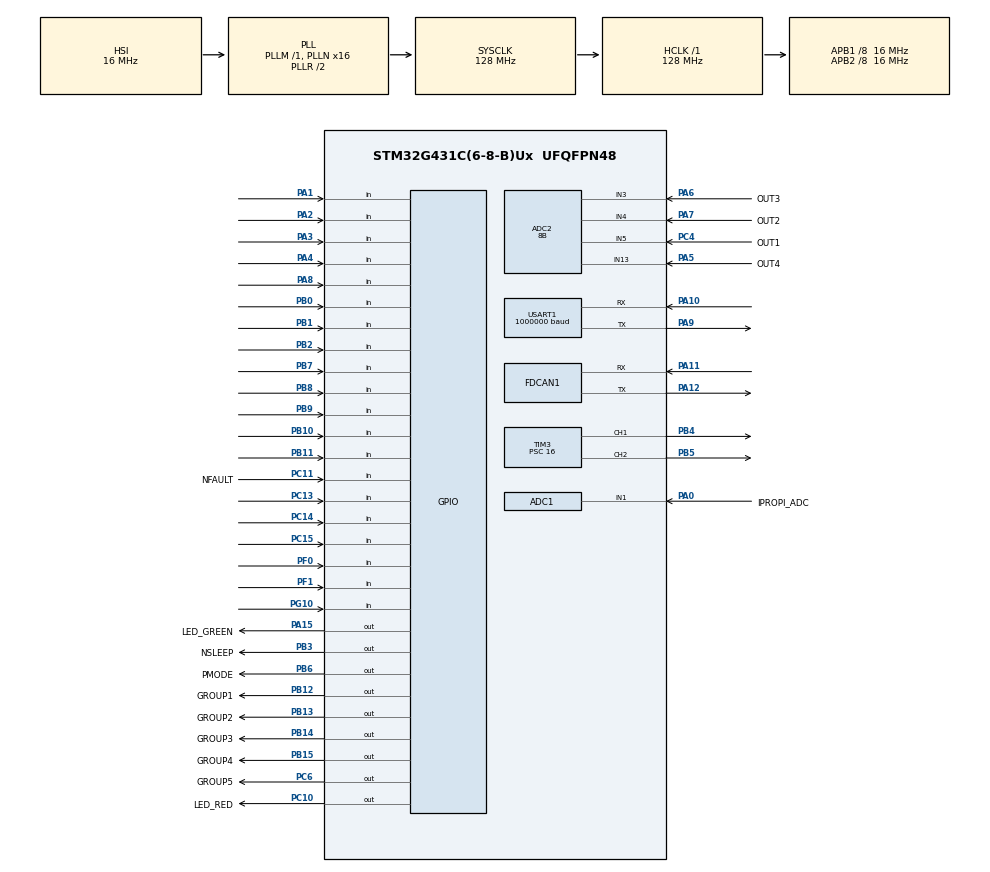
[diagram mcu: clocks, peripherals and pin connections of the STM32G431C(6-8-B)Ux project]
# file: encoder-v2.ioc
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ADC1.Channel-0\#ChannelRegularConversion=ADC_CHANNEL_1
ADC1.NbrOfConversionFlag=1
ADC1.OffsetNumber-0\#ChannelRegularConversion=ADC_OFFSET_NONE
ADC1.Rank-0\#ChannelRegularConversion=1
ADC1.SamplingTime-0\#ChannelRegularConversion=ADC_SAMPLETIME_2CYCLES_5
ADC1.master=1
ADC2.Channel-0\#ChannelRegularConversion=ADC_CHANNEL_5
ADC2.Channel-1\#ChannelRegularConversion=ADC_CHANNEL_4
ADC2.Channel-2\#ChannelRegularConversion=ADC_CHANNEL_3
ADC2.Channel-3\#ChannelRegularConversion=ADC_CHANNEL_13
ADC2.DMAContinuousRequests=ENABLE
ADC2.EOCSelection=ADC_EOC_SEQ_CONV
ADC2.NbrOfConversion=4
ADC2.NbrOfConversionFlag=1
ADC2.OffsetNumber-0\#ChannelRegularConversion=ADC_OFFSET_NONE
ADC2.OffsetNumber-1\#ChannelRegularConversion=ADC_OFFSET_NONE
ADC2.OffsetNumber-2\#ChannelRegularConversion=ADC_OFFSET_NONE
ADC2.OffsetNumber-3\#ChannelRegularConversion=ADC_OFFSET_NONE
ADC2.Rank-0\#ChannelRegularConversion=1
ADC2.Rank-1\#ChannelRegularConversion=2
ADC2.Rank-2\#ChannelRegularConversion=3
ADC2.Rank-3\#ChannelRegularConversion=4
ADC2.Resolution=ADC_RESOLUTION_8B
ADC2.SamplingTime-0\#ChannelRegularConversion=ADC_SAMPLETIME_47CYCLES_5
ADC2.SamplingTime-1\#ChannelRegularConversion=ADC_SAMPLETIME_47CYCLES_5
ADC2.SamplingTime-2\#ChannelRegularConversion=ADC_SAMPLETIME_47CYCLES_5
ADC2.SamplingTime-3\#ChannelRegularConversion=ADC_SAMPLETIME_47CYCLES_5
Dma.ADC2.0.Direction=DMA_PERIPH_TO_MEMORY
Dma.ADC2.0.EventEnable=DISABLE
Dma.ADC2.0.Instance=DMA1_Channel1
Dma.ADC2.0.MemDataAlignment=DMA_MDATAALIGN_BYTE
Dma.ADC2.0.MemInc=DMA_MINC_ENABLE
Dma.ADC2.0.Mode=DMA_NORMAL
Dma.ADC2.0.PeriphDataAlignment=DMA_PDATAALIGN_HALFWORD
Dma.ADC2.0.PeriphInc=DMA_PINC_DISABLE
Dma.ADC2.0.Polarity=HAL_DMAMUX_REQ_GEN_RISING
Dma.ADC2.0.Priority=DMA_PRIORITY_LOW
Dma.ADC2.0.RequestNumber=1
Dma.ADC2.0.SignalID=NONE
Dma.ADC2.0.SyncEnable=DISABLE
Dma.ADC2.0.SyncPolarity=HAL_DMAMUX_SYNC_NO_EVENT
Dma.ADC2.0.SyncRequestNumber=1
Dma.ADC2.0.SyncSignalID=NONE
Dma.Request0=ADC2
FDCAN1.AutoRetransmission=ENABLE
FDCAN1.ClockDivider=FDCAN_CLOCK_DIV1
FDCAN1.DataSyncJumpWidth=4
FDCAN1.DataTimeSeg1=11
FDCAN1.DataTimeSeg2=4
FDCAN1.NominalSyncJumpWidth=4
FDCAN1.NominalTimeSeg1=11
FDCAN1.NominalTimeSeg2=4
Mcu.Family=STM32G4
Mcu.Name=STM32G431C(6-8-B)Ux
Mcu.Package=UFQFPN48
NVIC.DMA1_Channel1_IRQn=true\:0\:0\:false\:false\:true\:false\:true
NVIC.FDCAN1_IT0_IRQn=true\:0\:0\:false\:false\:true\:true\:true
NVIC.PriorityGroup=NVIC_PRIORITYGROUP_4
PA0.GPIO_Label=IPROPI_ADC
PA0.Mode=IN1-Single-Ended
PA0.Signal=ADC1_IN1
PA1.GPIO_Mode=GPIO_MODE_INPUT
PA1.GPIO_PuPd=GPIO_PULLDOWN
PA1.Signal=GPIO_Input
PA10.Mode=Asynchronous
PA10.Signal=USART1_RX
PA11.Mode=FDCAN_Activate
PA11.Signal=FDCAN1_RX
PA12.Mode=FDCAN_Activate
PA12.Signal=FDCAN1_TX
PA13.Mode=Serial_Wire
PA13.Signal=SYS_JTMS-SWDIO
PA14.Mode=Serial_Wire
PA14.Signal=SYS_JTCK-SWCLK
PA15.GPIO_Label=LED_GREEN
PA15.Signal=GPIO_Output
PA2.GPIO_Mode=GPIO_MODE_INPUT
PA2.GPIO_PuPd=GPIO_PULLDOWN
PA2.Signal=GPIO_Input
PA3.GPIO_Mode=GPIO_MODE_INPUT
PA3.GPIO_PuPd=GPIO_PULLDOWN
PA3.Signal=GPIO_Input
PA4.GPIO_Mode=GPIO_MODE_INPUT
PA4.GPIO_PuPd=GPIO_PULLDOWN
PA4.Signal=GPIO_Input
PA5.GPIO_Label=OUT4
PA5.Mode=IN13-Single-Ended
PA5.Signal=ADC2_IN13
PA6.GPIO_Label=OUT3
PA6.Mode=IN3-Single-Ended
PA6.Signal=ADC2_IN3
PA7.GPIO_Label=OUT2
PA7.Mode=IN4-Single-Ended
PA7.Signal=ADC2_IN4
PA8.GPIO_Mode=GPIO_MODE_INPUT
PA8.GPIO_PuPd=GPIO_PULLDOWN
PA8.Signal=GPIO_Input
PA9.Mode=Asynchronous
PA9.Signal=USART1_TX
PB0.GPIO_Mode=GPIO_MODE_INPUT
PB0.GPIO_PuPd=GPIO_PULLDOWN
PB0.Signal=GPIO_Input
PB1.GPIO_Mode=GPIO_MODE_INPUT
PB1.GPIO_PuPd=GPIO_PULLDOWN
PB1.Signal=GPIO_Input
PB10.GPIO_Mode=GPIO_MODE_INPUT
PB10.GPIO_PuPd=GPIO_PULLDOWN
PB10.Signal=GPIO_Input
PB11.GPIO_Mode=GPIO_MODE_INPUT
PB11.GPIO_PuPd=GPIO_PULLDOWN
PB11.Signal=GPIO_Input
PB12.GPIO_Label=GROUP1
PB12.GPIO_Speed=GPIO_SPEED_FREQ_HIGH
PB12.PinState=GPIO_PIN_RESET
PB12.Signal=GPIO_Output
PB13.GPIO_Label=GROUP2
PB13.GPIO_Speed=GPIO_SPEED_FREQ_HIGH
PB13.PinState=GPIO_PIN_RESET
PB13.Signal=GPIO_Output
PB14.GPIO_Label=GROUP3
PB14.GPIO_Speed=GPIO_SPEED_FREQ_HIGH
PB14.Signal=GPIO_Output
PB15.GPIO_Label=GROUP4
PB15.GPIO_Speed=GPIO_SPEED_FREQ_HIGH
PB15.Signal=GPIO_Output
PB2.GPIO_Mode=GPIO_MODE_INPUT
PB2.GPIO_PuPd=GPIO_PULLDOWN
PB2.Signal=GPIO_Input
PB3.GPIO_Label=NSLEEP
PB3.Signal=GPIO_Output
PB4.Signal=S_TIM3_CH1
PB5.Signal=S_TIM3_CH2
PB6.GPIO_Label=PMODE
PB6.PinState=GPIO_PIN_SET
PB6.Signal=GPIO_Output
PB7.GPIO_Mode=GPIO_MODE_INPUT
PB7.GPIO_PuPd=GPIO_PULLDOWN
PB7.Signal=GPIO_Input
PB8-BOOT0.GPIO_Mode=GPIO_MODE_INPUT
PB8-BOOT0.GPIO_PuPd=GPIO_PULLDOWN
PB8-BOOT0.Signal=GPIO_Input
PB9.GPIO_Mode=GPIO_MODE_INPUT
PB9.GPIO_PuPd=GPIO_PULLDOWN
PB9.Signal=GPIO_Input
PC10.GPIO_Label=LED_RED
PC10.Signal=GPIO_Output
PC11.GPIO_Label=NFAULT
PC11.Signal=GPIO_Input
PC13.GPIO_Mode=GPIO_MODE_INPUT
PC13.GPIO_PuPd=GPIO_PULLDOWN
PC13.Signal=GPIO_Input
PC14-OSC32_IN.GPIO_Mode=GPIO_MODE_INPUT
PC14-OSC32_IN.GPIO_PuPd=GPIO_PULLDOWN
PC14-OSC32_IN.Signal=GPIO_Input
PC15-OSC32_OUT.GPIO_Mode=GPIO_MODE_INPUT
PC15-OSC32_OUT.GPIO_PuPd=GPIO_PULLDOWN
PC15-OSC32_OUT.Signal=GPIO_Input
PC4.GPIO_Label=OUT1
PC4.Mode=IN5-Single-Ended
PC4.Signal=ADC2_IN5
PC6.GPIO_Label=GROUP5
PC6.GPIO_Speed=GPIO_SPEED_FREQ_HIGH
PC6.Signal=GPIO_Output
PF0-OSC_IN.GPIO_Mode=GPIO_MODE_INPUT
PF0-OSC_IN.GPIO_PuPd=GPIO_PULLDOWN
PF0-OSC_IN.Signal=GPIO_Input
PF1-OSC_OUT.GPIO_Mode=GPIO_MODE_INPUT
PF1-OSC_OUT.GPIO_PuPd=GPIO_PULLDOWN
PF1-OSC_OUT.Signal=GPIO_Input
PG10-NRST.GPIO_PuPd=GPIO_PULLUP
PG10-NRST.Signal=GPIO_Input
ProjectManager.HeapSize=0x200
ProjectManager.StackSize=0x400
ProjectManager.TargetToolchain=STM32CubeIDE
RCC.ADC12Freq_Value=128000000
RCC.AHBFreq_Value=128000000
RCC.APB1CLKDivider=RCC_HCLK_DIV8
RCC.APB1Freq_Value=16000000
RCC.APB1TimFreq_Value=32000000
RCC.APB2CLKDivider=RCC_HCLK_DIV8
RCC.APB2Freq_Value=16000000
RCC.APB2TimFreq_Value=32000000
RCC.CortexFreq_Value=16000000
RCC.Cortex_Div=SYSTICK_CLKSOURCE_HCLK_DIV8
RCC.EXTERNAL_CLOCK_VALUE=12288000
RCC.HCLKFreq_Value=128000000
RCC.HSE_VALUE=8000000
RCC.HSI48_VALUE=48000000
RCC.HSI_VALUE=16000000
RCC.LSE_VALUE=32768
RCC.PLLN=16
RCC.SYSCLKFreq_VALUE=128000000
RCC.SYSCLKSource=RCC_SYSCLKSOURCE_PLLCLK
RCC.USBFreq_Value=128000000
RCC.VCOOutputFreq_Value=256000000
SH.S_TIM3_CH1.0=TIM3_CH1,PWM Generation1 CH1
SH.S_TIM3_CH2.0=TIM3_CH2,PWM Generation2 CH2
STMicroelectronics.X-CUBE-ALGOBUILD.1.1.0.LibraryCcDSPOoLibraryJjDSPOoLibrary=true
TIM3.Channel-PWM\ Generation1\ CH1=TIM_CHANNEL_1
TIM3.Channel-PWM\ Generation2\ CH2=TIM_CHANNEL_2
TIM3.PeriodNoDither=127
TIM3.Prescaler=16
USART1.BaudRate=1000000
USART1.VirtualMode-Asynchronous=VM_ASYNC
VP_SYS_VS_DBSignals.Mode=DisableDeadBatterySignals
board=custom

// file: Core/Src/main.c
/* USER CODE BEGIN Header */
/**
  ******************************************************************************
  * @file           : main.c
  * @brief          : Main program body
  ******************************************************************************
  * @attention
  *
  * <h2><center>&copy; Copyright (c) 2022 STMicroelectronics.
  * All rights reserved.</center></h2>
  *
  * This software component is licensed by ST under Ultimate Liberty license
  * SLA0044, the "License"; You may not use this file except in compliance with
  * the License. You may obtain a copy of the License at:
  *                             www.st.com/SLA0044
  *
  ******************************************************************************
  */
/* USER CODE END Header */
#include "main.h"
#include "adc.h"
#include "dma.h"
#include "fdcan.h"
#include "tim.h"
#include "usart.h"
#include "gpio.h"

/* USER CODE BEGIN Includes */
#include "scheduler.h"
#include "config.h"
/* USER CODE END Includes */

void SystemClock_Config(void);

int main(void)
{

  /* MCU Configuration--------------------------------------------------------*/

  /* Reset of all peripherals, Initializes the Flash interface and the Systick. */
  HAL_Init();

  /* Configure the system clock */
  SystemClock_Config();

  /* Initialize all configured peripherals */
  MX_GPIO_Init();
  MX_DMA_Init();
  MX_FDCAN1_Init();
  MX_ADC1_Init();
  MX_ADC2_Init();
  MX_TIM3_Init();
  MX_USART1_UART_Init();
  /* USER CODE BEGIN 2 */
  FlashWrite();
  /* USER CODE END 2 */

  /* Infinite loop */
  /* USER CODE BEGIN WHILE */
  while (1)
  {
    HAL_GPIO_TogglePin(LED_RED_GPIO_Port, LED_RED_Pin);
    SchedulerWaitFor(100);
    /* USER CODE END WHILE */

  }
}

void SystemClock_Config(void)
{
  RCC_OscInitTypeDef RCC_OscInitStruct = {0};
  RCC_ClkInitTypeDef RCC_ClkInitStruct = {0};
  RCC_PeriphCLKInitTypeDef PeriphClkInit = {0};

  /** Configure the main internal regulator output voltage
  */
  HAL_PWREx_ControlVoltageScaling(PWR_REGULATOR_VOLTAGE_SCALE1);
  /** Initializes the RCC Oscillators according to the specified parameters
  * in the RCC_OscInitTypeDef structure.
  */
  RCC_OscInitStruct.OscillatorType = RCC_OSCILLATORTYPE_HSI;
  RCC_OscInitStruct.HSIState = RCC_HSI_ON;
  RCC_OscInitStruct.HSICalibrationValue = RCC_HSICALIBRATION_DEFAULT;
  RCC_OscInitStruct.PLL.PLLState = RCC_PLL_ON;
  RCC_OscInitStruct.PLL.PLLSource = RCC_PLLSOURCE_HSI;
  RCC_OscInitStruct.PLL.PLLM = RCC_PLLM_DIV1;
  RCC_OscInitStruct.PLL.PLLN = 16;
  RCC_OscInitStruct.PLL.PLLP = RCC_PLLP_DIV2;
  RCC_OscInitStruct.PLL.PLLQ = RCC_PLLQ_DIV2;
  RCC_OscInitStruct.PLL.PLLR = RCC_PLLR_DIV2;
  if (HAL_RCC_OscConfig(&RCC_OscInitStruct) != HAL_OK)
  {
    Error_Handler();
  }
  /** Initializes the CPU, AHB and APB buses clocks
  */
  RCC_ClkInitStruct.ClockType = RCC_CLOCKTYPE_HCLK|RCC_CLOCKTYPE_SYSCLK
                              |RCC_CLOCKTYPE_PCLK1|RCC_CLOCKTYPE_PCLK2;
  RCC_ClkInitStruct.SYSCLKSource = RCC_SYSCLKSOURCE_PLLCLK;
  RCC_ClkInitStruct.AHBCLKDivider = RCC_SYSCLK_DIV1;
  RCC_ClkInitStruct.APB1CLKDivider = RCC_HCLK_DIV8;
  RCC_ClkInitStruct.APB2CLKDivider = RCC_HCLK_DIV8;

  if (HAL_RCC_ClockConfig(&RCC_ClkInitStruct, FLASH_LATENCY_3) != HAL_OK)
  {
    Error_Handler();
  }
  /** Initializes the peripherals clocks
  */
  PeriphClkInit.PeriphClockSelection = RCC_PERIPHCLK_USART1|RCC_PERIPHCLK_ADC12
                              |RCC_PERIPHCLK_FDCAN;
  PeriphClkInit.Usart1ClockSelection = RCC_USART1CLKSOURCE_PCLK2;
  PeriphClkInit.FdcanClockSelection = RCC_FDCANCLKSOURCE_PCLK1;
  PeriphClkInit.Adc12ClockSelection = RCC_ADC12CLKSOURCE_SYSCLK;
  if (HAL_RCCEx_PeriphCLKConfig(&PeriphClkInit) != HAL_OK)
  {
    Error_Handler();
  }
}

void Error_Handler(void)
{
  __disable_irq();
  while (1)
  {
  }
}

/************************ (C) COPYRIGHT STMicroelectronics *****END OF FILE****/
